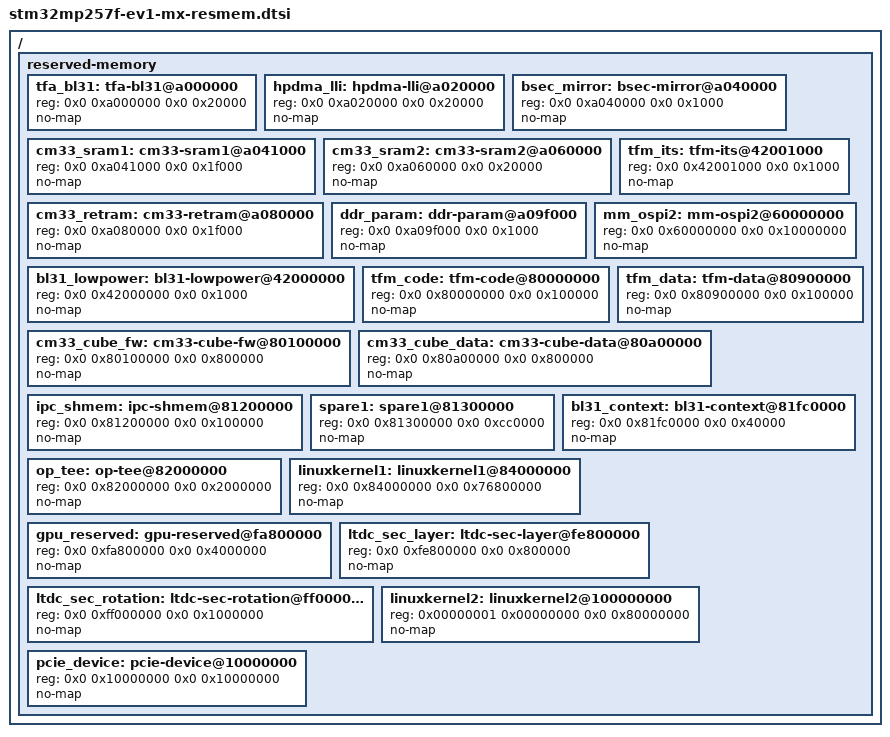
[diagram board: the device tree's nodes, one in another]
// SPDX-License-Identifier: (GPL-2.0-or-later OR BSD-3-Clause)
/*
 * Copyright (C) 2024, STMicroelectronics - All Rights Reserved
 * Author: STM32CubeMX code generation for STMicroelectronics.
 */

/* For more information on Device Tree configuration, please refer to
 * https://wiki.st.com/stm32mpu/wiki/Category:Device_tree_configuration
 */

 / {

	reserved-memory{

		#address-cells = <2>;
		#size-cells = <2>;
		ranges;

		tfa_bl31: tfa-bl31@a000000 {
			reg = <0x0 0xa000000 0x0 0x20000>;
			no-map;

			/* USER CODE BEGIN tfa_bl31 */
			/* USER CODE END tfa_bl31 */
		};

		hpdma_lli: hpdma-lli@a020000 {
			reg = <0x0 0xa020000 0x0 0x20000>;
			no-map;

			/* USER CODE BEGIN hpdma_lli */
			/* USER CODE END hpdma_lli */
		};

		bsec_mirror: bsec-mirror@a040000 {
			reg = <0x0 0xa040000 0x0 0x1000>;
			no-map;

			/* USER CODE BEGIN bsec_mirror */
			/* USER CODE END bsec_mirror */
		};

		cm33_sram1: cm33-sram1@a041000 {
			reg = <0x0 0xa041000 0x0 0x1f000>;
			no-map;

			/* USER CODE BEGIN cm33_sram1 */
			/* USER CODE END cm33_sram1 */
		};

		cm33_sram2: cm33-sram2@a060000 {
			reg = <0x0 0xa060000 0x0 0x20000>;
			no-map;

			/* USER CODE BEGIN cm33_sram2 */
			/* USER CODE END cm33_sram2 */
		};

		cm33_retram: cm33-retram@a080000 {
			reg = <0x0 0xa080000 0x0 0x1f000>;
			no-map;

			/* USER CODE BEGIN cm33_retram */
			/* USER CODE END cm33_retram */
		};

		ddr_param: ddr-param@a09f000 {
			reg = <0x0 0xa09f000 0x0 0x1000>;
			no-map;

			/* USER CODE BEGIN ddr_param */
			/* USER CODE END ddr_param */
		};

		bl31_lowpower: bl31-lowpower@42000000 {
			reg = <0x0 0x42000000 0x0 0x1000>;
			no-map;

			/* USER CODE BEGIN bl31_lowpower */
			/* USER CODE END bl31_lowpower */
		};

		tfm_its: tfm-its@42001000 {
			reg = <0x0 0x42001000 0x0 0x1000>;
			no-map;

			/* USER CODE BEGIN tfm_its */
			/* USER CODE END tfm_its */
		};

		mm_ospi2: mm-ospi2@60000000 {
			reg = <0x0 0x60000000 0x0 0x10000000>;
			no-map;

			/* USER CODE BEGIN mm_ospi2 */
			/* USER CODE END mm_ospi2 */
		};

		tfm_code: tfm-code@80000000 {
			reg = <0x0 0x80000000 0x0 0x100000>;
			no-map;

			/* USER CODE BEGIN tfm_code */
			/* USER CODE END tfm_code */
		};

		cm33_cube_fw: cm33-cube-fw@80100000 {
			reg = <0x0 0x80100000 0x0 0x800000>;
			no-map;

			/* USER CODE BEGIN cm33_cube_fw */
			/* USER CODE END cm33_cube_fw */
		};

		tfm_data: tfm-data@80900000 {
			reg = <0x0 0x80900000 0x0 0x100000>;
			no-map;

			/* USER CODE BEGIN tfm_data */
			/* USER CODE END tfm_data */
		};

		cm33_cube_data: cm33-cube-data@80a00000 {
			reg = <0x0 0x80a00000 0x0 0x800000>;
			no-map;

			/* USER CODE BEGIN cm33_cube_data */
			/* USER CODE END cm33_cube_data */
		};

		ipc_shmem: ipc-shmem@81200000 {
			reg = <0x0 0x81200000 0x0 0x100000>;
			no-map;

			/* USER CODE BEGIN ipc_shmem */
			/* USER CODE END ipc_shmem */
		};

		spare1: spare1@81300000 {
			reg = <0x0 0x81300000 0x0 0xcc0000>;
			no-map;

			/* USER CODE BEGIN spare1 */
			/* USER CODE END spare1 */
		};

		bl31_context: bl31-context@81fc0000 {
			reg = <0x0 0x81fc0000 0x0 0x40000>;
			no-map;

			/* USER CODE BEGIN bl31_context */
			/* USER CODE END bl31_context */
		};

		op_tee: op-tee@82000000 {
			reg = <0x0 0x82000000 0x0 0x2000000>;
			no-map;

			/* USER CODE BEGIN op_tee */
			/* USER CODE END op_tee */
		};

		linuxkernel1: linuxkernel1@84000000 {
			reg = <0x0 0x84000000 0x0 0x76800000>;
			no-map;

			/* USER CODE BEGIN linuxkernel1 */
			/* USER CODE END linuxkernel1 */
		};

		gpu_reserved: gpu-reserved@fa800000 {
			reg = <0x0 0xfa800000 0x0 0x4000000>;
			no-map;

			/* USER CODE BEGIN gpu_reserved */
			/* USER CODE END gpu_reserved */
		};

		ltdc_sec_layer: ltdc-sec-layer@fe800000 {
			reg = <0x0 0xfe800000 0x0 0x800000>;
			no-map;

			/* USER CODE BEGIN ltdc_sec_layer */
			/* USER CODE END ltdc_sec_layer */
		};

		ltdc_sec_rotation: ltdc-sec-rotation@ff000000 {
			reg = <0x0 0xff000000 0x0 0x1000000>;
			no-map;

			/* USER CODE BEGIN ltdc_sec_rotation */
			/* USER CODE END ltdc_sec_rotation */
		};

		linuxkernel2: linuxkernel2@100000000 {
			reg = <0x00000001 0x00000000 0x0 0x80000000>;
			no-map;

			/* USER CODE BEGIN linuxkernel2 */
			/* USER CODE END linuxkernel2 */
		};

		pcie_device: pcie-device@10000000 {
			reg = <0x0 0x10000000 0x0 0x10000000>;
			no-map;

			/* USER CODE BEGIN pcie_device */
			/* USER CODE END pcie_device */
		};

		/* USER CODE BEGIN reserved-memory */
		/* USER CODE END reserved-memory */
	};
};
